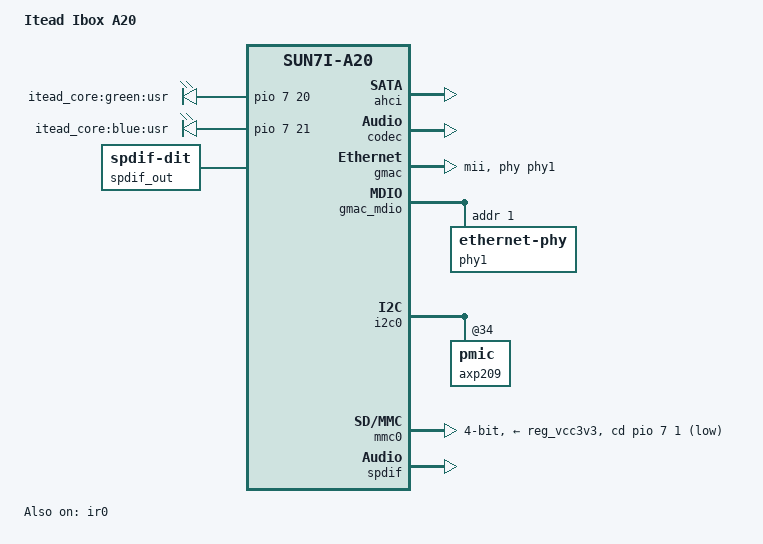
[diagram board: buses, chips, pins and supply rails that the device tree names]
/dts-v1/;
#include "sun7i-a20.dtsi"
#include "sunxi-itead-core-common.dtsi"
/ {
	model = "Itead Ibox A20";
	compatible = "itead,itead-ibox-a20", "allwinner,sun7i-a20";
	leds {
		compatible = "gpio-leds";
		pinctrl-names = "default";
		pinctrl-0 = <&led_pins_itead_core>;
		led-0 {
			label = "itead_core:green:usr";
			gpios = <&pio 7 20 GPIO_ACTIVE_HIGH>;
			default-state = "on";
		};
		led-1 {
			label = "itead_core:blue:usr";
			gpios = <&pio 7 21 GPIO_ACTIVE_HIGH>;
			default-state = "on";
		};
	};
	sound {
		compatible = "simple-audio-card";
		simple-audio-card,name = "On-board SPDIF";
		simple-audio-card,cpu {
			sound-dai = <&spdif>;
		};
		simple-audio-card,codec {
			sound-dai = <&spdif_out>;
		};
	};
	spdif_out: spdif-out {
		#sound-dai-cells = <0>;
		compatible = "linux,spdif-dit";
	};
};
&ahci {
	target-supply = <&reg_ahci_5v>;
	status = "okay";
};
&codec {
	status = "okay";
};
&gmac {
	pinctrl-names = "default";
	pinctrl-0 = <&gmac_mii_pins>;
	phy-handle = <&phy1>;
	phy-mode = "mii";
	status = "okay";
};
&gmac_mdio {
	phy1: ethernet-phy@1 {
		reg = <1>;
	};
};
&i2c0 {
	axp209: pmic@34 {
		interrupt-parent = <&nmi_intc>;
		interrupts = <0 IRQ_TYPE_LEVEL_LOW>;
	};
};
&ir0 {
	pinctrl-names = "default";
	pinctrl-0 = <&ir0_rx_pin>;
	status = "okay";
};
&mmc0 {
	vmmc-supply = <&reg_vcc3v3>;
	bus-width = <4>;
	cd-gpios = <&pio 7 1 GPIO_ACTIVE_LOW>;  
	status = "okay";
};
&pio {
	led_pins_itead_core: led-pins {
		pins = "PH20","PH21";
		function = "gpio_out";
		drive-strength = <20>;
	};
};
&reg_ahci_5v {
	status = "okay";
};
&spdif {
	pinctrl-names = "default";
	pinctrl-0 = <&spdif_tx_pin>;
	status = "okay";
};
